# SF32LB52x register map
File version: 1.0
CPU: CM33 r0p1, little endian, MPU, FPU, 3 interrupt priority bits
Registers are 32-bit, read-write, reset 0x0 unless marked. A register's access mark holds for its fields unless they carry their own. Offsets are from the block's base; [hi:lo] are bit positions; 'fields as' and 'values as' point back to an identical list.

## HPSYS_RCC
Base 0x50000000
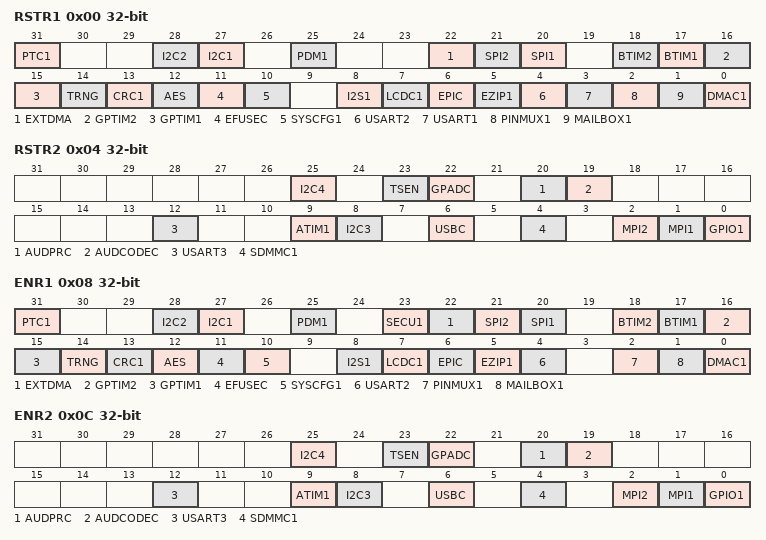
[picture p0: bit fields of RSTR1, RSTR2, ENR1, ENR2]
0x00 RSTR1 — Reset Register 1
  [31] PTC1 — 0 - no reset; 1 - reset
  [28] I2C2 — 0 - no reset; 1 - reset
  [27] I2C1 — 0 - no reset; 1 - reset
  [25] PDM1 — 0 - no reset; 1 - reset
  [22] EXTDMA — 0 - no reset; 1 - reset
  [21] SPI2 — 0 - no reset; 1 - reset
  [20] SPI1 — 0 - no reset; 1 - reset
  [18] BTIM2 — 0 - no reset; 1 - reset
  [17] BTIM1 — 0 - no reset; 1 - reset
  [16] GPTIM2 — 0 - no reset; 1 - reset
  [15] GPTIM1 — 0 - no reset; 1 - reset
  [14] TRNG — 0 - no reset; 1 - reset
  [13] CRC1 — 0 - no reset; 1 - reset
  [12] AES — 0 - no reset; 1 - reset
  [11] EFUSEC — 0 - no reset; 1 - reset
  [10] SYSCFG1 — 0 - no reset; 1 - reset
  [8] I2S1 — 0 - no reset; 1 - reset
  [7] LCDC1 — 0 - no reset; 1 - reset
  [6] EPIC — 0 - no reset; 1 - reset
  [5] EZIP1 — 0 - no reset; 1 - reset
  [4] USART2 — 0 - no reset; 1 - reset
  [3] USART1 — 0 - no reset; 1 - reset
  [2] PINMUX1 — 0 - no reset; 1 - reset
  [1] MAILBOX1 — 0 - no reset; 1 - reset
  [0] DMAC1 — 0 - no reset; 1 - reset
0x04 RSTR2 — Reset Register 2
  [25] I2C4 — 0 - no reset; 1 - reset
  [23] TSEN — 0 - no reset; 1 - reset
  [22] GPADC — 0 - no reset; 1 - reset
  [20] AUDPRC — 0 - no reset; 1 - reset
  [19] AUDCODEC — 0 - no reset; 1 - reset
  [12] USART3 — 0 - no reset; 1 - reset
  [9] ATIM1 — 0 - no reset; 1 - reset
  [8] I2C3 — 0 - no reset; 1 - reset
  [6] USBC — 0 - no reset; 1 - reset
  [4] SDMMC1 — 0 - no reset; 1 - reset
  [2] MPI2 — 0 - no reset; 1 - reset
  [1] MPI1 — 0 - no reset; 1 - reset
  [0] GPIO1 — 0 - no reset; 1 - reset
0x08 ENR1 — Enable Register 1
  [31] PTC1 — write 1 to set module enable, write 0 to disable module
  [28] I2C2 — write 1 to set module enable, write 0 to disable module
  [27] I2C1 — write 1 to set module enable, write 0 to disable module
  [25] PDM1 — write 1 to set module enable, write 0 to disable module
  [23] SECU1 — write 1 to set module enable, write 0 to disable module
  [22] EXTDMA — write 1 to set module enable, write 0 to disable module
  [21] SPI2 — write 1 to set module enable, write 0 to disable module
  [20] SPI1 — write 1 to set module enable, write 0 to disable module
  [18] BTIM2 — write 1 to set module enable, write 0 to disable module
  [17] BTIM1 — write 1 to set module enable, write 0 to disable module
  [16] GPTIM2 — write 1 to set module enable, write 0 to disable module
  [15] GPTIM1 — write 1 to set module enable, write 0 to disable module
  [14] TRNG — write 1 to set module enable, write 0 to disable module
  [13] CRC1 — write 1 to set module enable, write 0 to disable module
  [12] AES — write 1 to set module enable, write 0 to disable module
  [11] EFUSEC — write 1 to set module enable, write 0 to disable module
  [10] SYSCFG1 — write 1 to set module enable, write 0 to disable module
  [8] I2S1 — write 1 to set module enable, write 0 to disable module
  [7] LCDC1 — write 1 to set module enable, write 0 to disable module
  [6] EPIC — write 1 to set module enable, write 0 to disable module
  [5] EZIP1 — write 1 to set module enable, write 0 to disable module
  [4] USART2 — write 1 to set module enable, write 0 to disable module
  [2] PINMUX1 — write 1 to set module enable, write 0 to disable module
  [1] MAILBOX1 — write 1 to set module enable, write 0 to disable module
  [0] DMAC1 — write 1 to set module enable, write 0 to disable module
0x0C ENR2 — Enable Register 2
  [25] I2C4 — write 1 to set module enable, write 0 to disable module
  [23] TSEN — write 1 to set module enable, write 0 to disable module
  [22] GPADC — write 1 to set module enable, write 0 to disable module
  [20] AUDPRC — write 1 to set module enable, write 0 to disable module
  [19] AUDCODEC — write 1 to set module enable, write 0 to disable module
  [12] USART3 — write 1 to set module enable, write 0 to disable module
  [9] ATIM1 — write 1 to set module enable, write 0 to disable module
  [8] I2C3 — write 1 to set module enable, write 0 to disable module
  [6] USBC — write 1 to set module enable, write 0 to disable module
  [4] SDMMC1 — write 1 to set module enable, write 0 to disable module
  [2] MPI2 — write 1 to set module enable, write 0 to disable module
  [1] MPI1 — write 1 to set module enable, write 0 to disable module
  [0] GPIO1 — write 1 to set module enable, write 0 to disable module
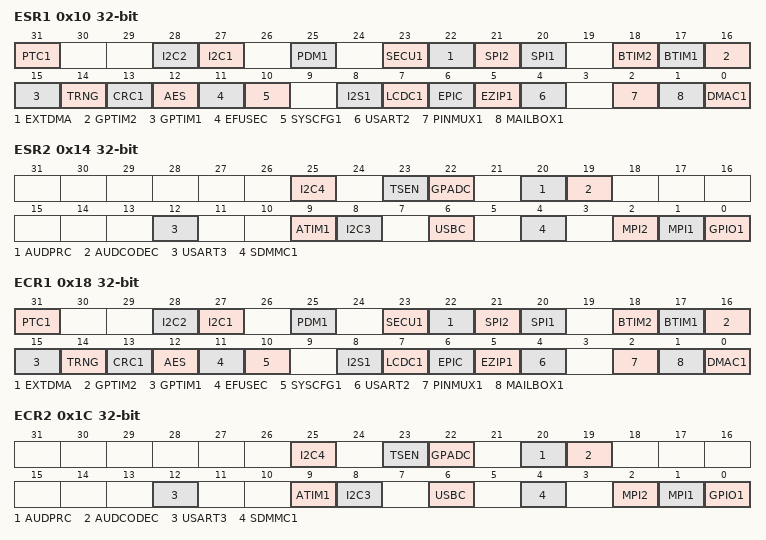
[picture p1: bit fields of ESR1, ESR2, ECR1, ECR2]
0x10 ESR1 — Enable Set Register 1
  [31] PTC1 — write 1 to set module enable, write 0 has no effect
  [28] I2C2 — write 1 to set module enable, write 0 has no effect
  [27] I2C1 — write 1 to set module enable, write 0 has no effect
  [25] PDM1 — write 1 to set module enable, write 0 has no effect
  [23] SECU1 — write 1 to set module enable, write 0 has no effect
  [22] EXTDMA — write 1 to set module enable, write 0 has no effect
  [21] SPI2 — write 1 to set module enable, write 0 has no effect
  [20] SPI1 — write 1 to set module enable, write 0 has no effect
  [18] BTIM2 — write 1 to set module enable, write 0 has no effect
  [17] BTIM1 — write 1 to set module enable, write 0 has no effect
  [16] GPTIM2 — write 1 to set module enable, write 0 has no effect
  [15] GPTIM1 — write 1 to set module enable, write 0 has no effect
  [14] TRNG — write 1 to set module enable, write 0 has no effect
  [13] CRC1 — write 1 to set module enable, write 0 has no effect
  [12] AES — write 1 to set module enable, write 0 has no effect
  [11] EFUSEC — write 1 to set module enable, write 0 has no effect
  [10] SYSCFG1 — write 1 to set module enable, write 0 has no effect
  [8] I2S1 — write 1 to set module enable, write 0 has no effect
  [7] LCDC1 — write 1 to set module enable, write 0 has no effect
  [6] EPIC — write 1 to set module enable, write 0 has no effect
  [5] EZIP1 — write 1 to set module enable, write 0 has no effect
  [4] USART2 — write 1 to set module enable, write 0 has no effect
  [2] PINMUX1 — write 1 to set module enable, write 0 has no effect
  [1] MAILBOX1 — write 1 to set module enable, write 0 has no effect
  [0] DMAC1 — write 1 to set module enable, write 0 has no effect
0x14 ESR2 — Enable Set Register 2
  [25] I2C4 — write 1 to set module enable, write 0 has no effect
  [23] TSEN — write 1 to set module enable, write 0 has no effect
  [22] GPADC — write 1 to set module enable, write 0 has no effect
  [20] AUDPRC — write 1 to set module enable, write 0 has no effect
  [19] AUDCODEC — write 1 to set module enable, write 0 has no effect
  [12] USART3 — write 1 to set module enable, write 0 has no effect
  [9] ATIM1 — write 1 to set module enable, write 0 has no effect
  [8] I2C3 — write 1 to set module enable, write 0 has no effect
  [6] USBC — write 1 to set module enable, write 0 has no effect
  [4] SDMMC1 — write 1 to set module enable, write 0 has no effect
  [2] MPI2 — write 1 to set module enable, write 0 has no effect
  [1] MPI1 — write 1 to set module enable, write 0 has no effect
  [0] GPIO1 — write 1 to set module enable, write 0 has no effect
0x18 ECR1 — Enable Clear Register 1
  [31] PTC1 — write 1 to clear module enable, write 0 has no effect
  [28] I2C2 — write 1 to clear module enable, write 0 has no effect
  [27] I2C1 — write 1 to clear module enable, write 0 has no effect
  [25] PDM1 — write 1 to clear module enable, write 0 has no effect
  [23] SECU1 — write 1 to clear module enable, write 0 has no effect
  [22] EXTDMA — write 1 to clear module enable, write 0 has no effect
  [21] SPI2 — write 1 to clear module enable, write 0 has no effect
  [20] SPI1 — write 1 to clear module enable, write 0 has no effect
  [18] BTIM2 — write 1 to clear module enable, write 0 has no effect
  [17] BTIM1 — write 1 to clear module enable, write 0 has no effect
  [16] GPTIM2 — write 1 to clear module enable, write 0 has no effect
  [15] GPTIM1 — write 1 to clear module enable, write 0 has no effect
  [14] TRNG — write 1 to clear module enable, write 0 has no effect
  [13] CRC1 — write 1 to clear module enable, write 0 has no effect
  [12] AES — write 1 to clear module enable, write 0 has no effect
  [11] EFUSEC — write 1 to clear module enable, write 0 has no effect
  [10] SYSCFG1 — write 1 to clear module enable, write 0 has no effect
  [8] I2S1 — write 1 to clear module enable, write 0 has no effect
  [7] LCDC1 — write 1 to clear module enable, write 0 has no effect
  [6] EPIC — write 1 to clear module enable, write 0 has no effect
  [5] EZIP1 — write 1 to clear module enable, write 0 has no effect
  [4] USART2 — write 1 to clear module enable, write 0 has no effect
  [2] PINMUX1 — write 1 to clear module enable, write 0 has no effect
  [1] MAILBOX1 — write 1 to clear module enable, write 0 has no effect
  [0] DMAC1 — write 1 to clear module enable, write 0 has no effect
0x1C ECR2 — Enable Clear Register 2
  [25] I2C4 — write 1 to clear module enable, write 0 has no effect
  [23] TSEN — write 1 to clear module enable, write 0 has no effect
  [22] GPADC — write 1 to clear module enable, write 0 has no effect
  [20] AUDPRC — write 1 to clear module enable, write 0 has no effect
  [19] AUDCODEC — write 1 to clear module enable, write 0 has no effect
  [12] USART3 — write 1 to clear module enable, write 0 has no effect
  [9] ATIM1 — write 1 to clear module enable, write 0 has no effect
  [8] I2C3 — write 1 to clear module enable, write 0 has no effect
  [6] USBC — write 1 to clear module enable, write 0 has no effect
  [4] SDMMC1 — write 1 to clear module enable, write 0 has no effect
  [2] MPI2 — write 1 to clear module enable, write 0 has no effect
  [1] MPI1 — write 1 to clear module enable, write 0 has no effect
  [0] GPIO1 — write 1 to clear module enable, write 0 has no effect
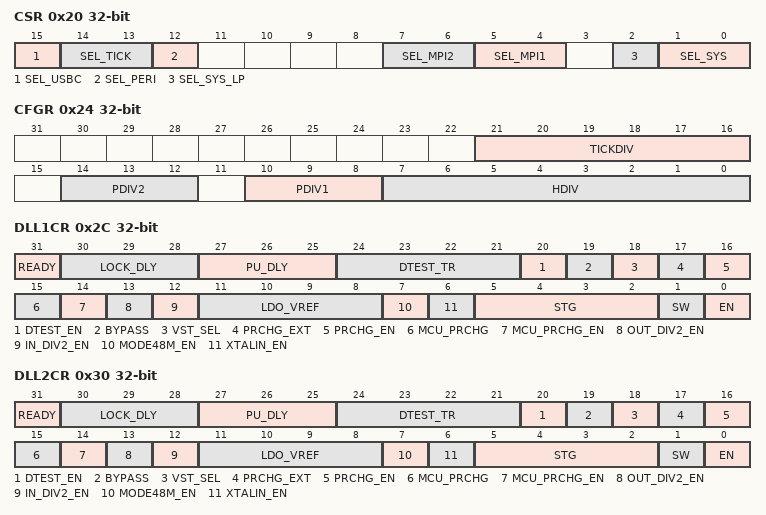
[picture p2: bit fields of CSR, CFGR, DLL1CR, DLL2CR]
0x20 CSR — Clock Select Register
  [15] SEL_USBC — select USB source clock 0 - clk_hpsys; 1 - clk_dll2
  [14:13] SEL_TICK — select clock source for systick reference 0 - clk_rtc; 1 - reserved; 2 - clk_hrc48; 3 - clk_hxt48
  [12] SEL_PERI — select clk_peri_hpsys source used by USART/SPI/I2C/GPTIM2/BTIM2 0 - clk_hrc48; 1 - clk_hxt48
  [7:6] SEL_MPI2 — selet MPI2 function clock 0 - clk_peri_hpsys; 1 - clk_dll1; 2 - clk_dll2; 3 - reserved
  [5:4] SEL_MPI1 — selet MPI1 function clock 0 - clk_peri_hpsys; 1 - clk_dll1; 2 - clk_dll2; 3 - reserved
  [2] SEL_SYS_LP — select clk_hpsys source 0 - selected by SEL_SYS; 1 - clk_wdt
  [1:0] SEL_SYS — select clk_hpsys source 0 - clk_hrc48; 1 - clk_hxt48; 2 - reserved; 3 - clk_dll1
0x24 CFGR — Clock Configuration Register
  [21:16] TICKDIV — systick reference clock is systick reference clock source (selected by SEL_TICK) devided by TICKDIV
  [14:12] PDIV2 — pclk2_hpsys = hclk_hpsys / (2^PDIV2), by default divided by 16
  [10:8] PDIV1 — pclk_hpsys = hclk_hpsys / (2^PDIV1), by default divided by 2
  [7:0] HDIV — hclk_hpsys = clk_hpsys / HDIV if HDIV=0, hclk_hpsys = clk_hpsys
0x28 USBCR — USBC Control Register
  [2:0] DIV — USB function clock is USB source clock divided by DIV. After divider, USB function clock must be 60MHz. For example, if USBC clock source is 240MHz clk_dll2, DIV should be 4.
0x2C DLL1CR — DLL1 Control Register
  [31] READY — 0: dll not ready 1: dll ready
  [30:28] LOCK_DLY
  [27:25] PU_DLY
  [24:21] DTEST_TR
  [20] DTEST_EN
  [19] BYPASS
  [18] VST_SEL
  [17] PRCHG_EXT
  [16] PRCHG_EN
  [15] MCU_PRCHG
  [14] MCU_PRCHG_EN
  [13] OUT_DIV2_EN — 0: dll output not divided 1: dll output divided by 2
  [12] IN_DIV2_EN
  [11:8] LDO_VREF
  [7] MODE48M_EN
  [6] XTALIN_EN
  [5:2] STG — DLL lock freqency is decided by STG. DLL output frequency is (STG+1)*24MHz e.g. STG=9,DLL output is 240M
  [1] SW
  [0] EN — 0: dll disabled 1: dll enabled
0x30 DLL2CR — DLL2 Control Register
  fields as DLL1CR
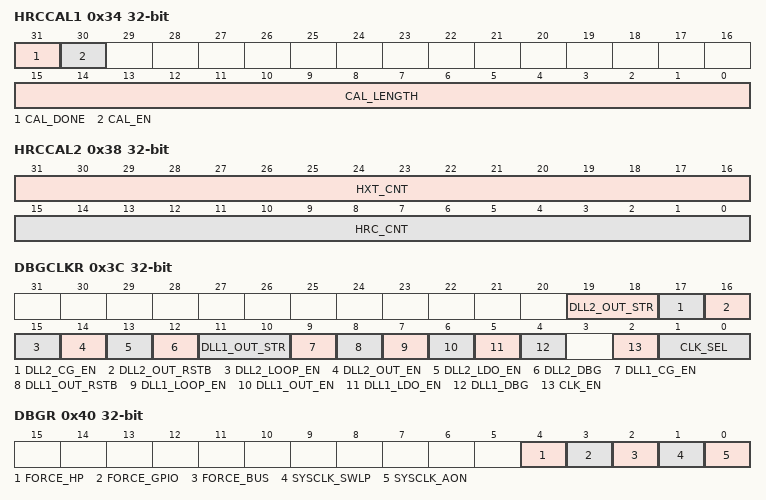
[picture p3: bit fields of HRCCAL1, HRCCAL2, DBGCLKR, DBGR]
0x34 HRCCAL1 — HRC Calibration Register 1
  [31] CAL_DONE — Calibration done. After a new calibration started, results should be processed only when cal_done asserted.
  [30] CAL_EN — Calibration enble. Set to 0 to clear result, then set to 1 to start a new calibration
  [15:0] CAL_LENGTH — Target clk_hxt48 cycles during calibration
0x38 HRCCAL2 — HRC Calibration Register 2
  [31:16] HXT_CNT — Total clk_hxt48 cycles during calibration
  [15:0] HRC_CNT — Total clk_hrc48 cycles during calibration
0x3C DBGCLKR — Debug Clock Register
  [19:18] DLL2_OUT_STR — for debug only
  [17] DLL2_CG_EN — for debug only
  [16] DLL2_OUT_RSTB — for debug only
  [15] DLL2_LOOP_EN — for debug only
  [14] DLL2_OUT_EN — for debug only
  [13] DLL2_LDO_EN — for debug only
  [12] DLL2_DBG — for debug only
  [11:10] DLL1_OUT_STR — for debug only
  [9] DLL1_CG_EN — for debug only
  [8] DLL1_OUT_RSTB — for debug only
  [7] DLL1_LOOP_EN — for debug only
  [6] DLL1_OUT_EN — for debug only
  [5] DLL1_LDO_EN — for debug only
  [4] DLL1_DBG — for debug only
  [2] CLK_EN — for debug only
  [1:0] CLK_SEL — for debug only
0x40 DBGR — Debug Register
  [4] FORCE_HP — for debug only
  [3] FORCE_GPIO — for debug only
  [2] FORCE_BUS — for debug only
  [1] SYSCLK_SWLP — for debug only
  [0] SYSCLK_AON — for debug only
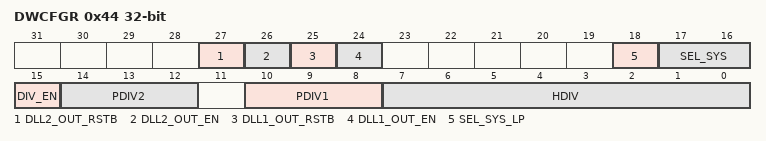
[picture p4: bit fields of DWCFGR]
0x44 DWCFGR — Deep WFI mode Clock Configuration Register
  [27] DLL2_OUT_RSTB — for debug only
  [26] DLL2_OUT_EN — for debug only
  [25] DLL1_OUT_RSTB — for debug only
  [24] DLL1_OUT_EN — for debug only
  [18] SEL_SYS_LP — select clk_hpsys source during deep WFI 0 - selected by SEL_SYS; 1 - clk_wdt
  [17:16] SEL_SYS — select clk_hpsys source during deep WFI 0 - clk_hrc48; 1 - clk_hxt48; 2 - RSVD; 3 - clk_dll1
  [15] DIV_EN — enable PDIV1, PDIV2 and HDIV reconfiguration during deep wfi
  [14:12] PDIV2 — pclk2_hpsys = hclk_hpsys / (2^PDIV2) during deep wfi
  [10:8] PDIV1 — pclk_hpsys = hclk_hpsys / (2^PDIV1) during deep wfi
  [7:0] HDIV — hclk_hpsys = clk_hpsys / HDIV during deep wfi
